# ISS_CAMERARX_CORE1 register map
Vendor: Texas Instruments
Peripheral module from a debugger description file (folder omap4460).
Registers are 32-bit, access not given, reset 0x427 unless marked. A register's access mark holds for its fields unless they carry their own. Offsets are as the file gives them; lines under a group give offsets from that group; [hi:lo] are bit positions; {n}, {i} and the like mark numbered series; 'fields as' and 'values as' point back to an identical list; <NAME> marks a mode.

## ISS_CAMERARX_CORE1
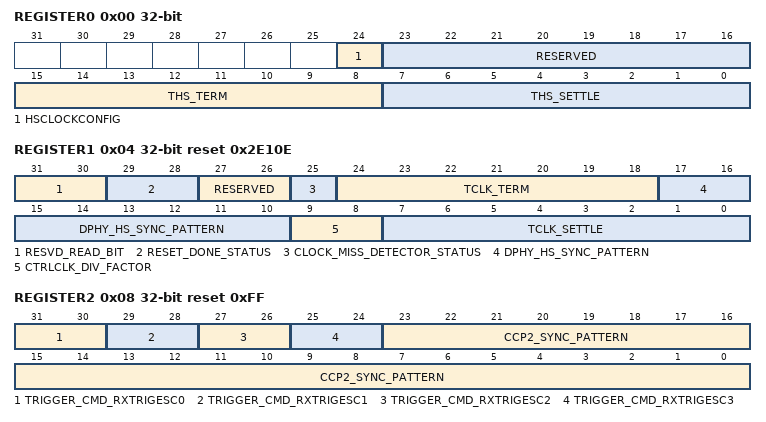
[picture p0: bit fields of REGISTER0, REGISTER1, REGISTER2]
0x00 REGISTER0 — First register
  [24] HSCLOCKCONFIG rw — Disable clock missing detector
  [23:16] RESERVED ro — Read returns zero
  [15:8] THS_TERM rw — THS_TERM timing parameter in multiples of DDR clock Effective time for enabling of termination = synchronizer delay + timer delay + LPRX delay + combinational routing delay ~ (1–2)* DDRCLK + THS-TERM + ~ (1 –15) ns Programmed value = ceil(12.5 / DDR clock period) –1
  [7:0] THS_SETTLE rw — THS_SETTLE timing parameter in multiples of DDR clock frequency Effective THS_SETTLE seen on line (starting to look for sync pattern) = synchronizer delay + timer delay + LPRX delay + combinational routing delay – pipeline delay in HS data path. ~ (1–2)* DDRCLK + THS-SETTLE + ~ (1–15) ns –1*DDRCLK Programmed value = ceil(90 ns / DDR clock period) + 3
0x04 REGISTER1 reset 0x2E10E — Second register
  [31:30] RESVD_READ_BIT — Reserved bit (access NA)
  [29:28] RESET_DONE_STATUS ro — Reset done read bits.
  [27:26] RESERVED rw — Write 0 for future compatibility.
  [25] CLOCK_MISS_DETECTOR_STATUS ro — 1: Error in clock missing detector.
    0=Clock missing detector successful
  [24:18] TCLK_TERM rw — TCLK_TERM timing parameter in multiples of CTRLCLK Effective time for enabling of termination = synchronizer delay + timer delay + LPRX delay + combinational routing delay ~ (1–2)* CTRLCLK + TCLK_TERM + ~ (1–15) ns Programmed value = ceil(9.5 / CTRLCLK period) – 1
  [17:10] DPHY_HS_SYNC_PATTERN rw — DPHY mode HS sync pattern in byte order (reverse of received order) See,
  [9:8] CTRLCLK_DIV_FACTOR rw — Divide factor for CTRLCLK for CLKMISS detector
  [7:0] TCLK_SETTLE rw — TCLK_SETTLE timing parameter in multiples of CTRLCLK Clock Effective TCLK_SETTLE = synchronizer delay + timer delay + LPRX delay + combinational routing delay ~ (1–2)* CTRLCLK + Tclk-settle + ~ (1 –15) ns Programmed value = max[3, ceil(155 ns/CTRLCLK period) –1]
0x08 REGISTER2 access per field reset 0xFF — Third register
  [31-2n:30-2n] TRIGGER_CMD_RXTRIGESC{n} rw (n=0..3) — Mapping of Trigger escape entry command to PPI output RXTRIGGERESC{n}
  [23:0] CCP2_SYNC_PATTERN ro — CCP2 mode sync pattern in byte order See ,
